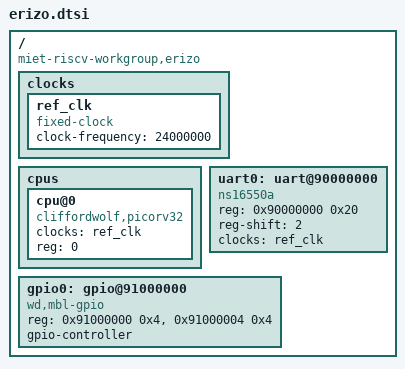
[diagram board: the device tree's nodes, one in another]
// SPDX-License-Identifier: GPL-2.0-only

/dts-v1/;

/ {
	compatible = "miet-riscv-workgroup,erizo";

	#address-cells = <1>;
	#size-cells = <1>;

	clocks {
		ref_clk: ref_clk {
			#clock-cells = <0>;
			compatible = "fixed-clock";
			clock-frequency = <24000000>;
		};
	};

	cpus {
		#address-cells = <1>;
		#size-cells = <0>;

		cpu@0 {
			device_type = "cpu";
			compatible = "cliffordwolf,picorv32";
			clocks = <&ref_clk>;
			reg = <0>;
		};
	};

	uart0: uart@90000000 {
		compatible = "ns16550a";
		reg = <0x90000000 0x20>;
		reg-shift = <2>;
		clocks = <&ref_clk>;
	};

	gpio0: gpio@91000000 {
		compatible = "wd,mbl-gpio";
		reg-names = "dat", "dirout";
		reg = <0x91000000 0x4>,
			<0x91000004 0x4>;
		#gpio-cells = <2>;
		gpio-controller;
	};
};
